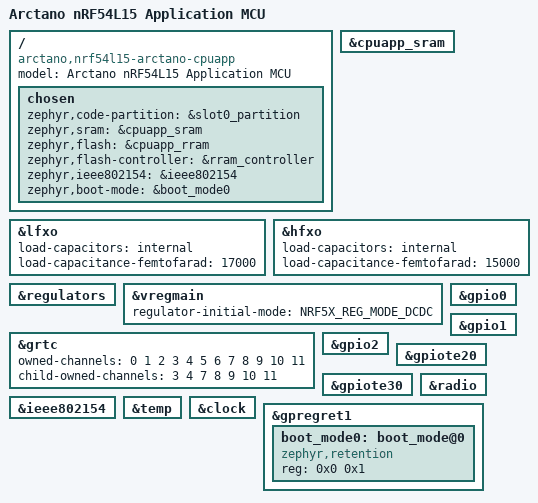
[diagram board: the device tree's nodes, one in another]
/dts-v1/;
#include <nordic/nrf54l15_cpuapp.dtsi>
#include "nrf54l15_arctano-pinctrl.dtsi"

/ {
	model = "Arctano nRF54L15 Application MCU";
	compatible = "arctano,nrf54l15-arctano-cpuapp";

	chosen {
		zephyr,code-partition = &slot0_partition;
		zephyr,sram = &cpuapp_sram;
		zephyr,flash = &cpuapp_rram;
		zephyr,flash-controller = &rram_controller;
		zephyr,ieee802154 = &ieee802154;
		zephyr,boot-mode = &boot_mode0;
	};
};

&cpuapp_sram {
	status = "okay";
};

&lfxo {
	load-capacitors = "internal";
	load-capacitance-femtofarad = <17000>;
};

&hfxo {
	load-capacitors = "internal";
	load-capacitance-femtofarad = <15000>;
};

&regulators {
	status = "okay";
};

&vregmain {
	status = "okay";
	regulator-initial-mode = <NRF5X_REG_MODE_DCDC>;
};

&grtc {
	owned-channels = <0 1 2 3 4 5 6 7 8 9 10 11>;
	child-owned-channels = <3 4 7 8 9 10 11>;
	status = "okay";
};

&gpio0 {
	status = "okay";
};

&gpio1 {
	status = "okay";
};

&gpio2 {
	status = "okay";
};

&gpiote20 {
	status = "okay";
};

&gpiote30 {
	status = "okay";
};

&radio {
	status = "okay";
};

&ieee802154 {
	status = "okay";
};

&temp {
	status = "okay";
};

&clock {
	status = "okay";
};

&gpregret1 {
	status = "okay";

	boot_mode0: boot_mode@0 {
		compatible = "zephyr,retention";
		status = "okay";
		reg = <0x0 0x1>;
	};
};

#include <vendor/nordic/nrf54l15_cpuapp_partition.dtsi>
